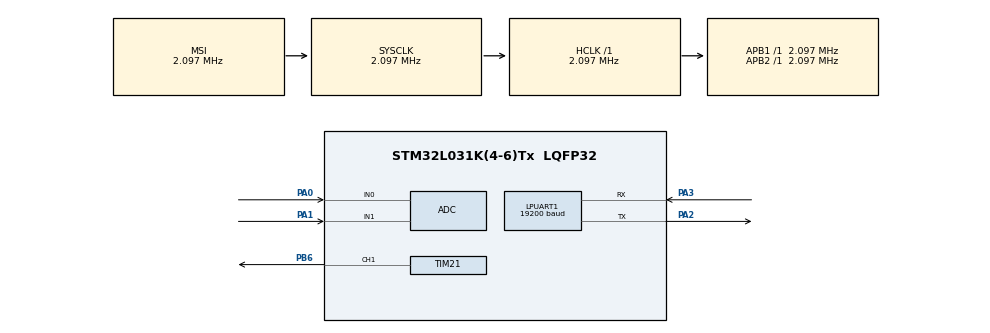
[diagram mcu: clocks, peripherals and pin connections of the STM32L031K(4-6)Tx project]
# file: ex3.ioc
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ADC.ContinuousConvMode=ENABLE
ADC.DMAContinuousRequests=DISABLE
Dma.ADC.0.Direction=DMA_PERIPH_TO_MEMORY
Dma.ADC.0.Instance=DMA1_Channel1
Dma.ADC.0.MemDataAlignment=DMA_MDATAALIGN_HALFWORD
Dma.ADC.0.MemInc=DMA_MINC_ENABLE
Dma.ADC.0.Mode=DMA_CIRCULAR
Dma.ADC.0.PeriphDataAlignment=DMA_PDATAALIGN_HALFWORD
Dma.ADC.0.PeriphInc=DMA_PINC_DISABLE
Dma.ADC.0.Priority=DMA_PRIORITY_LOW
Dma.Request0=ADC
LPUART1.BaudRate=19200
LPUART1.WordLength=UART_WORDLENGTH_8B
Mcu.Family=STM32L0
Mcu.Name=STM32L031K(4-6)Tx
Mcu.Package=LQFP32
NVIC.DMA1_Channel1_IRQn=true\:0\:0\:false\:false\:true\:false\:true\:true
PA0-CK_IN.Mode=IN0
PA0-CK_IN.Signal=ADC_IN0
PA1.Mode=IN1
PA1.Signal=ADC_IN1
PA13.Mode=Serial_Wire
PA13.Signal=SYS_SWDIO
PA14.Mode=Serial_Wire
PA14.Signal=SYS_SWCLK
PA2.Mode=Asynchronous
PA2.Signal=LPUART1_TX
PA3.Mode=Asynchronous
PA3.Signal=LPUART1_RX
PB6.Signal=S_TIM21_CH1
PC14-OSC32_IN.Mode=LSE-External-Oscillator
PC14-OSC32_IN.Signal=RCC_OSC32_IN
PC15-OSC32_OUT.Mode=LSE-External-Oscillator
PC15-OSC32_OUT.Signal=RCC_OSC32_OUT
ProjectManager.HeapSize=0x200
ProjectManager.StackSize=0x400
ProjectManager.TargetToolchain=STM32CubeIDE
RCC.ADCFreq_Value=16000000
RCC.AHBFreq_Value=2097000
RCC.APB1Freq_Value=2097000
RCC.APB1TimFreq_Value=2097000
RCC.APB2Freq_Value=2097000
RCC.APB2TimFreq_Value=2097000
RCC.HCLKFreq_Value=2097000
RCC.HSE_VALUE=8000000
RCC.HSI16_VALUE=16000000
RCC.HSI_VALUE=16000000
RCC.MSI_VALUE=2097000
RCC.SYSCLKFreq_VALUE=2097000
RCC.VCOOutputFreq_Value=48000000
SH.S_TIM21_CH1.0=TIM21_CH1,PWM Generation1 CH1
TIM21.AutoReloadPreload=TIM_AUTORELOAD_PRELOAD_ENABLE
TIM21.Channel-PWM\ Generation1\ CH1=TIM_CHANNEL_1
TIM21.Prescaler=0
VP_TIM21_VS_ClockSourceINT.Mode=Internal
board=custom

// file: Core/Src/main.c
/* USER CODE BEGIN Header */
/**
  ******************************************************************************
  * @file           : main.c
  * @brief          : Main program body
  ******************************************************************************
  * @attention
  *
  * Copyright (c) 2025 STMicroelectronics.
  * All rights reserved.
  *
  * This software is licensed under terms that can be found in the LICENSE file
  * in the root directory of this software component.
  * If no LICENSE file comes with this software, it is provided AS-IS.
  *
  ******************************************************************************
  */
/* USER CODE END Header */
#include "main.h"

ADC_HandleTypeDef hadc;
DMA_HandleTypeDef hdma_adc;

UART_HandleTypeDef hlpuart1;

TIM_HandleTypeDef htim21;

void SystemClock_Config(void);
static void MX_GPIO_Init(void);
static void MX_DMA_Init(void);
static void MX_TIM21_Init(void);
static void MX_ADC_Init(void);
static void MX_LPUART1_UART_Init(void);

int main(void)
{

  /* MCU Configuration--------------------------------------------------------*/

  /* Reset of all peripherals, Initializes the Flash interface and the Systick. */
  HAL_Init();

  /* Configure the system clock */
  SystemClock_Config();

  /* Initialize all configured peripherals */
  MX_GPIO_Init();
  MX_DMA_Init();
  MX_TIM21_Init();
  MX_ADC_Init();
  MX_LPUART1_UART_Init();
  /* USER CODE BEGIN 2 */
  /*
  uint8_t register_address = 0x00;
  uint16_t slave_address = 0x50;
  HAL_TIM_PWM_Start(&htim21, TIM_CHANNEL_1);
  int32_t CH1_DC = 0;
  TIM21->ARR = 5241;
  TIM21->PSC = 0;*/

  uint8_t on[] = "ADC[0]: ";
  uint8_t off[] = "ADC[1]: ";
  uint8_t iteration = 0;
  //TIM21->CCR1 = 2000;
  /* USER CODE END 2 */

  /* Infinite loop */
  /* USER CODE BEGIN WHILE */
  uint16_t adc_val[2];
  HAL_ADC_Start_DMA(&hadc, adc_val, 4);
  while (1)
  {
    /* USER CODE END WHILE */

    /* USER CODE BEGIN 3 */
	  	/*
	  while(CH1_DC < 5000){
		  TIM21->CCR1 = CH1_DC;
		  CH1_DC += 70;
		  HAL_Delay(1);
	  }
	  while(CH1_DC > 0){
		  TIM21->CCR1 = CH1_DC;
		  CH1_DC -= 70;
		  HAL_Delay(1);
	  }*/

	  char str_buffer[100];
	  HAL_ADC_Start(&hadc);
	  HAL_Delay(200);
	        sprintf(str_buffer, "%s %u TEST %u\r\n",on, (unsigned int) adc_val[0], (unsigned int) adc_val[1]);

	        //HAL_GPIO_WritePin(GPIOB, GPIO_PIN_0, GPIO_PIN_SET);
	        HAL_Delay(500);

	        HAL_UART_Transmit(&hlpuart1,str_buffer,strlen(str_buffer),5000);
	  //      HAL_UART_Transmit(&hlpuart1,&iteration,sizeof(iteration),100);
	  //      HAL_UART_Transmit(&hlpuart1,newline,sizeof(newline),100);
	        HAL_Delay(500);
	        //sprintf(str_buffer, "%s %u \r\n",off, (unsigned int) adc_val[1]);

	        //HAL_GPIO_WritePin(GPIOB, GPIO_PIN_0, GPIO_PIN_RESET);

	        //HAL_UART_Transmit(&hlpuart1,str_buffer,strlen(str_buffer),5000);
	  //      HAL_UART_Transmit(&hlpuart1,&iteration,sizeof(iteration),100);
	  //      HAL_UART_Transmit(&hlpuart1,newline,sizeof(newline),100);
	        iteration = iteration + 1;

  }
  /* USER CODE END 3 */
}

void SystemClock_Config(void)
{
  RCC_OscInitTypeDef RCC_OscInitStruct = {0};
  RCC_ClkInitTypeDef RCC_ClkInitStruct = {0};
  RCC_PeriphCLKInitTypeDef PeriphClkInit = {0};

  /** Configure the main internal regulator output voltage
  */
  __HAL_PWR_VOLTAGESCALING_CONFIG(PWR_REGULATOR_VOLTAGE_SCALE1);

  /** Initializes the RCC Oscillators according to the specified parameters
  * in the RCC_OscInitTypeDef structure.
  */
  RCC_OscInitStruct.OscillatorType = RCC_OSCILLATORTYPE_MSI;
  RCC_OscInitStruct.MSIState = RCC_MSI_ON;
  RCC_OscInitStruct.MSICalibrationValue = 0;
  RCC_OscInitStruct.MSIClockRange = RCC_MSIRANGE_5;
  RCC_OscInitStruct.PLL.PLLState = RCC_PLL_NONE;
  if (HAL_RCC_OscConfig(&RCC_OscInitStruct) != HAL_OK)
  {
    Error_Handler();
  }

  /** Initializes the CPU, AHB and APB buses clocks
  */
  RCC_ClkInitStruct.ClockType = RCC_CLOCKTYPE_HCLK|RCC_CLOCKTYPE_SYSCLK
                              |RCC_CLOCKTYPE_PCLK1|RCC_CLOCKTYPE_PCLK2;
  RCC_ClkInitStruct.SYSCLKSource = RCC_SYSCLKSOURCE_MSI;
  RCC_ClkInitStruct.AHBCLKDivider = RCC_SYSCLK_DIV1;
  RCC_ClkInitStruct.APB1CLKDivider = RCC_HCLK_DIV1;
  RCC_ClkInitStruct.APB2CLKDivider = RCC_HCLK_DIV1;

  if (HAL_RCC_ClockConfig(&RCC_ClkInitStruct, FLASH_LATENCY_0) != HAL_OK)
  {
    Error_Handler();
  }
  PeriphClkInit.PeriphClockSelection = RCC_PERIPHCLK_LPUART1;
  PeriphClkInit.Lpuart1ClockSelection = RCC_LPUART1CLKSOURCE_PCLK1;
  if (HAL_RCCEx_PeriphCLKConfig(&PeriphClkInit) != HAL_OK)
  {
    Error_Handler();
  }
}

static void MX_ADC_Init(void)
{

  ADC_ChannelConfTypeDef sConfig = {0};

  /** Configure the global features of the ADC (Clock, Resolution, Data Alignment and number of conversion)
  */
  hadc.Instance = ADC1;
  hadc.Init.OversamplingMode = DISABLE;
  hadc.Init.ClockPrescaler = ADC_CLOCK_SYNC_PCLK_DIV1;
  hadc.Init.Resolution = ADC_RESOLUTION_12B;
  hadc.Init.SamplingTime = ADC_SAMPLETIME_1CYCLE_5;
  hadc.Init.ScanConvMode = ADC_SCAN_DIRECTION_FORWARD;
  hadc.Init.DataAlign = ADC_DATAALIGN_RIGHT;
  hadc.Init.ContinuousConvMode = ENABLE;
  hadc.Init.DiscontinuousConvMode = DISABLE;
  hadc.Init.ExternalTrigConvEdge = ADC_EXTERNALTRIGCONVEDGE_NONE;
  hadc.Init.ExternalTrigConv = ADC_SOFTWARE_START;
  hadc.Init.DMAContinuousRequests = DISABLE;
  hadc.Init.EOCSelection = ADC_EOC_SINGLE_CONV;
  hadc.Init.Overrun = ADC_OVR_DATA_PRESERVED;
  hadc.Init.LowPowerAutoWait = DISABLE;
  hadc.Init.LowPowerFrequencyMode = ENABLE;
  hadc.Init.LowPowerAutoPowerOff = DISABLE;
  if (HAL_ADC_Init(&hadc) != HAL_OK)
  {
    Error_Handler();
  }

  /** Configure for the selected ADC regular channel to be converted.
  */
  sConfig.Channel = ADC_CHANNEL_0;
  sConfig.Rank = ADC_RANK_CHANNEL_NUMBER;
  if (HAL_ADC_ConfigChannel(&hadc, &sConfig) != HAL_OK)
  {
    Error_Handler();
  }

  /** Configure for the selected ADC regular channel to be converted.
  */
  sConfig.Channel = ADC_CHANNEL_1;
  if (HAL_ADC_ConfigChannel(&hadc, &sConfig) != HAL_OK)
  {
    Error_Handler();
  }

}

static void MX_LPUART1_UART_Init(void)
{

  hlpuart1.Instance = LPUART1;
  hlpuart1.Init.BaudRate = 19200;
  hlpuart1.Init.WordLength = UART_WORDLENGTH_8B;
  hlpuart1.Init.StopBits = UART_STOPBITS_1;
  hlpuart1.Init.Parity = UART_PARITY_NONE;
  hlpuart1.Init.Mode = UART_MODE_TX_RX;
  hlpuart1.Init.HwFlowCtl = UART_HWCONTROL_NONE;
  hlpuart1.Init.OneBitSampling = UART_ONE_BIT_SAMPLE_DISABLE;
  hlpuart1.AdvancedInit.AdvFeatureInit = UART_ADVFEATURE_NO_INIT;
  if (HAL_UART_Init(&hlpuart1) != HAL_OK)
  {
    Error_Handler();
  }

}

static void MX_TIM21_Init(void)
{

  TIM_ClockConfigTypeDef sClockSourceConfig = {0};
  TIM_MasterConfigTypeDef sMasterConfig = {0};
  TIM_OC_InitTypeDef sConfigOC = {0};

  htim21.Instance = TIM21;
  htim21.Init.Prescaler = 0;
  htim21.Init.CounterMode = TIM_COUNTERMODE_UP;
  htim21.Init.Period = 65535;
  htim21.Init.ClockDivision = TIM_CLOCKDIVISION_DIV1;
  htim21.Init.AutoReloadPreload = TIM_AUTORELOAD_PRELOAD_ENABLE;
  if (HAL_TIM_Base_Init(&htim21) != HAL_OK)
  {
    Error_Handler();
  }
  sClockSourceConfig.ClockSource = TIM_CLOCKSOURCE_INTERNAL;
  if (HAL_TIM_ConfigClockSource(&htim21, &sClockSourceConfig) != HAL_OK)
  {
    Error_Handler();
  }
  if (HAL_TIM_PWM_Init(&htim21) != HAL_OK)
  {
    Error_Handler();
  }
  sMasterConfig.MasterOutputTrigger = TIM_TRGO_RESET;
  sMasterConfig.MasterSlaveMode = TIM_MASTERSLAVEMODE_DISABLE;
  if (HAL_TIMEx_MasterConfigSynchronization(&htim21, &sMasterConfig) != HAL_OK)
  {
    Error_Handler();
  }
  sConfigOC.OCMode = TIM_OCMODE_PWM1;
  sConfigOC.Pulse = 0;
  sConfigOC.OCPolarity = TIM_OCPOLARITY_HIGH;
  sConfigOC.OCFastMode = TIM_OCFAST_DISABLE;
  if (HAL_TIM_PWM_ConfigChannel(&htim21, &sConfigOC, TIM_CHANNEL_1) != HAL_OK)
  {
    Error_Handler();
  }
  HAL_TIM_MspPostInit(&htim21);

}

static void MX_DMA_Init(void)
{

  /* DMA controller clock enable */
  __HAL_RCC_DMA1_CLK_ENABLE();

  /* DMA interrupt init */
  /* DMA1_Channel1_IRQn interrupt configuration */
  HAL_NVIC_SetPriority(DMA1_Channel1_IRQn, 0, 0);
  HAL_NVIC_EnableIRQ(DMA1_Channel1_IRQn);

}

static void MX_GPIO_Init(void)
{

  /* GPIO Ports Clock Enable */
  __HAL_RCC_GPIOC_CLK_ENABLE();
  __HAL_RCC_GPIOA_CLK_ENABLE();
  __HAL_RCC_GPIOB_CLK_ENABLE();

}

void Error_Handler(void)
{
  __disable_irq();
  while (1)
  {
  }
}
